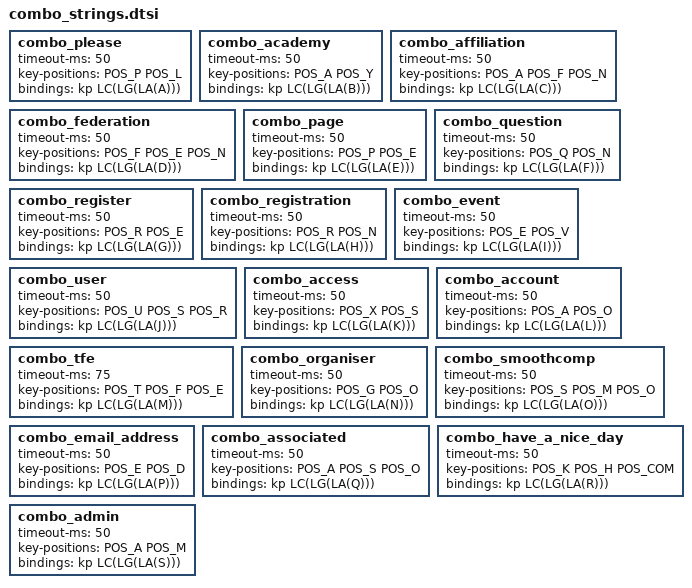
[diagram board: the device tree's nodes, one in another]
#include "keypos.dtsi"

// please
combo_please {
  timeout-ms = <50>;
  key-positions = <POS_P POS_L>;
  bindings = <&kp LC(LG(LA(A)))>;
};

// academy
combo_academy {
  timeout-ms = <50>;
  key-positions = <POS_A POS_Y>;
  bindings = <&kp LC(LG(LA(B)))>;
};

// affiliation
combo_affiliation {
  timeout-ms = <50>;
  key-positions = <POS_A POS_F POS_N>;
  bindings = <&kp LC(LG(LA(C)))>;
};

// federation
combo_federation {
  timeout-ms = <50>;
  key-positions = <POS_F POS_E POS_N>;
  bindings = <&kp LC(LG(LA(D)))>;
};

// page
combo_page {
  timeout-ms = <50>;
  key-positions = <POS_P POS_E>;
  bindings = <&kp LC(LG(LA(E)))>;
};

// question
combo_question {
  timeout-ms = <50>;
  key-positions = <POS_Q POS_N>;
  bindings = <&kp LC(LG(LA(F)))>;
};

// register
combo_register {
  timeout-ms = <50>;
  key-positions = <POS_R POS_E>;
  bindings = <&kp LC(LG(LA(G)))>;
};

// registration
combo_registration {
  timeout-ms = <50>;
  key-positions = <POS_R POS_N>;
  bindings = <&kp LC(LG(LA(H)))>;
};

//event
combo_event {
  timeout-ms = <50>;
  key-positions = <POS_E POS_V>;
  bindings = <&kp LC(LG(LA(I)))>;
};

//user
combo_user {
  timeout-ms = <50>;
  key-positions = <POS_U POS_S POS_R>;
  bindings = <&kp LC(LG(LA(J)))>;
};

//access
combo_access {
  timeout-ms = <50>;
  key-positions = <POS_X POS_S>;
  bindings = <&kp LC(LG(LA(K)))>;
};

//account
combo_account {
  timeout-ms = <50>;
  key-positions = <POS_A POS_O>;
  bindings = <&kp LC(LG(LA(L)))>;
};

//Thank you for your email.\n
combo_tfe {
  timeout-ms = <75>;
  key-positions = <POS_T POS_F POS_E>;
  bindings = <&kp LC(LG(LA(M)))>;
};

//organiser
combo_organiser {
  timeout-ms = <50>;
  key-positions = <POS_G POS_O>;
  bindings = <&kp LC(LG(LA(N)))>;
};

//Smoothcomp
combo_smoothcomp {
  timeout-ms = <50>;
  key-positions = <POS_S POS_M POS_O>;
  bindings = <&kp LC(LG(LA(O)))>;
};

//email address
combo_email_address {
  timeout-ms = <50>;
  key-positions = <POS_E POS_D>;
  bindings = <&kp LC(LG(LA(P)))>;
};

//associated
combo_associated {
  timeout-ms = <50>;
  key-positions = <POS_A POS_S POS_O>;
  bindings = <&kp LC(LG(LA(Q)))>;
};

//Have a nice day!
combo_have_a_nice_day {
  timeout-ms = <50>;
  key-positions = <POS_K POS_H POS_COM>;
  bindings = <&kp LC(LG(LA(R)))>;
};

//admin
combo_admin {
  timeout-ms = <50>;
  key-positions = <POS_A POS_M>;
  bindings = <&kp LC(LG(LA(S)))>;
};








/*   timeout-ms = <75>; */
/*   key-positions = <3 16>; */
/*   bindings = <&kp A)>; */
/* }; */

/* ---------------------------------------- */

/*  combo_ctrl_tab { */
/*   timeout-ms = <50>; */
/*   key-positions = <POS_F POS_T>; // adjust to your actual keys */
/*   bindings = <&kp LC(TAB)>; */
/* }; */
/**/
/*  combo_ctrl_shift_tab { */
/*   timeout-ms = <50>; */
/*   key-positions = <POS_W POS_F>; // adjust to your actual keys */
/*   bindings = <&kp LC(LS(TAB))>; */
/* }; */
/**/
/* combo_delete_line { */
/*   timeout-ms = <50>; */
/*   key-positions = <10 11>;  // chord Q + P */
/*   bindings = <&kp LA(BSPC)>; */
/* }; */
/**/
/* combo_delete_word_back  { */
/*   timeout-ms = <50>; */
/*   key-positions = <POS_R POS_S POS_T>;  // chord Q + P */
/*   bindings = <&kp LA(LS(BSPC))>; */
/* }; */


/* combo_jump_one_word_back { */
/*   timeout-ms = <50>; */
/*   key-positions = <POS_X POS_C>; */
/*   bindings = <&kp LA(LEFT)>; */
/* }; */

/* combo_jump_one_word_forward  { */
/*   timeout-ms = <50>; */
/*   key-positions = <POS_COM POS_DOT>;  // chord Q + P */
/*   bindings = <&kp LA(RIGHT)>; */
/* }; */
/**/
/* combo_select_all  { */
/*   timeout-ms = <50>; */
/*   key-positions = <POS_W POS_F POS_P>;  // chord Q + P */
/*   bindings = <&kp LGUI(A)>; */
/* }; */
